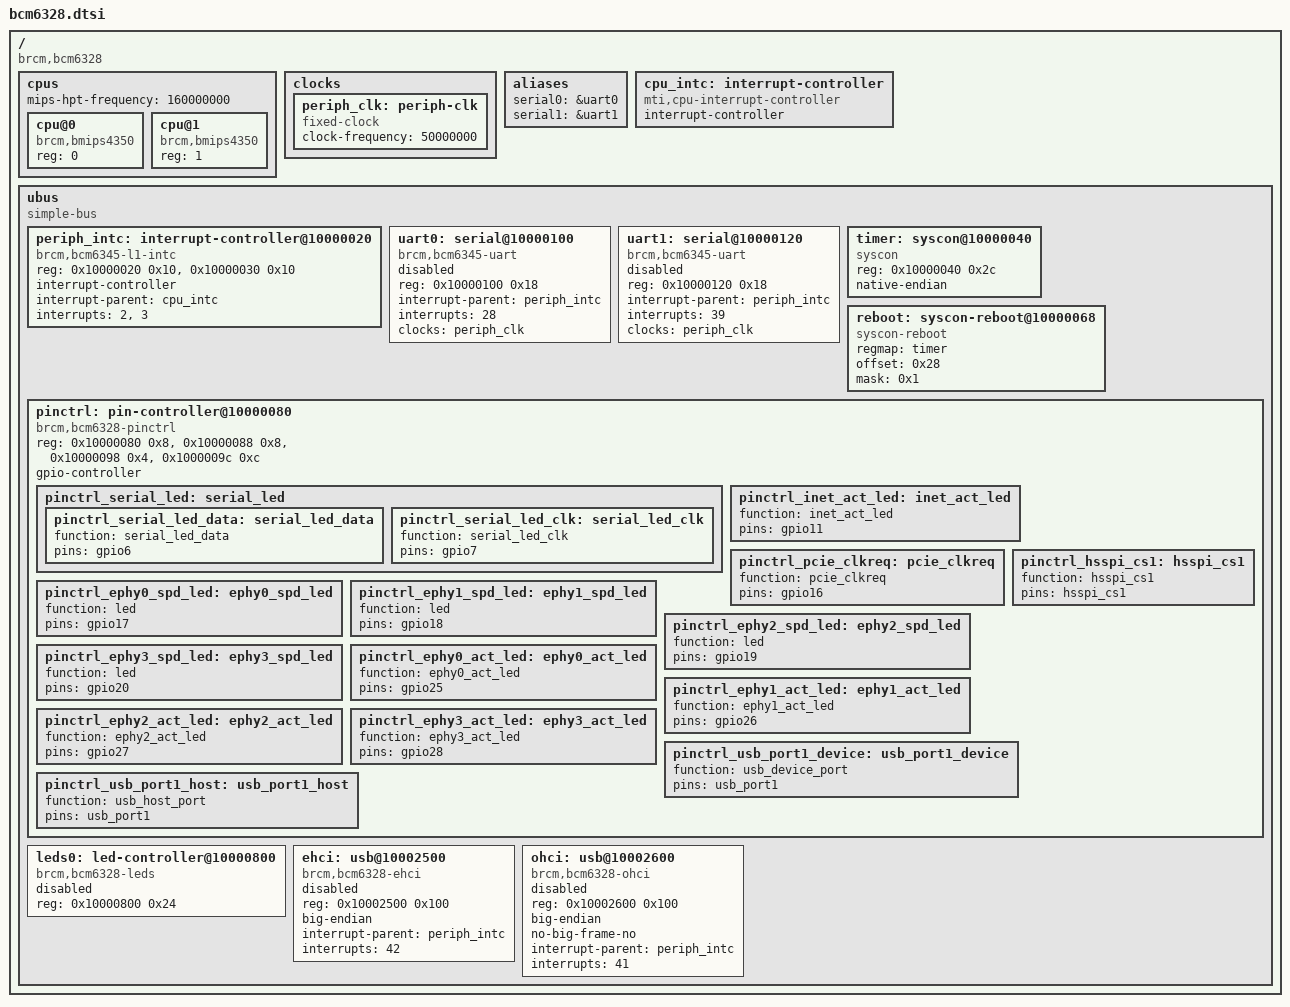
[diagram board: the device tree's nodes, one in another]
/ {
	#address-cells = <1>;
	#size-cells = <1>;
	compatible = "brcm,bcm6328";

	cpus {
		#address-cells = <1>;
		#size-cells = <0>;

		mips-hpt-frequency = <160000000>;

		cpu@0 {
			compatible = "brcm,bmips4350";
			device_type = "cpu";
			reg = <0>;
		};

		cpu@1 {
			compatible = "brcm,bmips4350";
			device_type = "cpu";
			reg = <1>;
		};
	};

	clocks {
		periph_clk: periph-clk {
			compatible = "fixed-clock";
			#clock-cells = <0>;
			clock-frequency = <50000000>;
		};
	};

	aliases {
		serial0 = &uart0;
		serial1 = &uart1;
	};

	cpu_intc: interrupt-controller {
		#address-cells = <0>;
		compatible = "mti,cpu-interrupt-controller";

		interrupt-controller;
		#interrupt-cells = <1>;
	};

	ubus {
		#address-cells = <1>;
		#size-cells = <1>;

		compatible = "simple-bus";
		ranges;

		periph_intc: interrupt-controller@10000020 {
			compatible = "brcm,bcm6345-l1-intc";
			reg = <0x10000020 0x10>,
			      <0x10000030 0x10>;

			interrupt-controller;
			#interrupt-cells = <1>;

			interrupt-parent = <&cpu_intc>;
			interrupts = <2>, <3>;
		};

		uart0: serial@10000100 {
			compatible = "brcm,bcm6345-uart";
			reg = <0x10000100 0x18>;
			interrupt-parent = <&periph_intc>;
			interrupts = <28>;
			clocks = <&periph_clk>;
			status = "disabled";
		};

		uart1: serial@10000120 {
			compatible = "brcm,bcm6345-uart";
			reg = <0x10000120 0x18>;
			interrupt-parent = <&periph_intc>;
			interrupts = <39>;
			clocks = <&periph_clk>;
			status = "disabled";
		};

		timer: syscon@10000040 {
			compatible = "syscon";
			reg = <0x10000040 0x2c>;
			native-endian;
		};

		reboot: syscon-reboot@10000068 {
			compatible = "syscon-reboot";
			regmap = <&timer>;
			offset = <0x28>;
			mask = <0x1>;
		};

		pinctrl: pin-controller@10000080 {
			compatible = "brcm,bcm6328-pinctrl";
			reg = <0x10000080 0x8>,
			      <0x10000088 0x8>,
			      <0x10000098 0x4>,
			      <0x1000009c 0xc>;
			reg-names = "dirout", "dat", "mode", "mux";

			gpio-controller;
			#gpio-cells = <2>;

			pinctrl_serial_led: serial_led {
				pinctrl_serial_led_data: serial_led_data {
					function = "serial_led_data";
					pins = "gpio6";
				};

				pinctrl_serial_led_clk: serial_led_clk {
					function = "serial_led_clk";
					pins = "gpio7";
				};
			};

			pinctrl_inet_act_led: inet_act_led {
				function = "inet_act_led";
				pins = "gpio11";
			};

			pinctrl_pcie_clkreq: pcie_clkreq {
				function = "pcie_clkreq";
				pins = "gpio16";
			};

			pinctrl_ephy0_spd_led: ephy0_spd_led {
				function = "led";
				pins = "gpio17";
			};

			pinctrl_ephy1_spd_led: ephy1_spd_led {
				function = "led";
				pins = "gpio18";
			};

			pinctrl_ephy2_spd_led: ephy2_spd_led {
				function = "led";
				pins = "gpio19";
			};

			pinctrl_ephy3_spd_led: ephy3_spd_led {
				function = "led";
				pins = "gpio20";
			};

			pinctrl_ephy0_act_led: ephy0_act_led {
				function = "ephy0_act_led";
				pins = "gpio25";
			};

			pinctrl_ephy1_act_led: ephy1_act_led {
				function = "ephy1_act_led";
				pins = "gpio26";
			};

			pinctrl_ephy2_act_led: ephy2_act_led {
				function = "ephy2_act_led";
				pins = "gpio27";
			};

			pinctrl_ephy3_act_led: ephy3_act_led {
				function = "ephy3_act_led";
				pins = "gpio28";
			};

			pinctrl_hsspi_cs1: hsspi_cs1 {
				function = "hsspi_cs1";
				pins = "hsspi_cs1";
			};

			pinctrl_usb_port1_device: usb_port1_device {
				function = "usb_device_port";
				pins = "usb_port1";
			};

			pinctrl_usb_port1_host: usb_port1_host {
				function = "usb_host_port";
				pins = "usb_port1";
			};
		};

		leds0: led-controller@10000800 {
			#address-cells = <1>;
			#size-cells = <0>;
			compatible = "brcm,bcm6328-leds";
			reg = <0x10000800 0x24>;
			status = "disabled";
		};

		ehci: usb@10002500 {
			compatible = "brcm,bcm6328-ehci", "generic-ehci";
			reg = <0x10002500 0x100>;
			big-endian;
			interrupt-parent = <&periph_intc>;
			interrupts = <42>;
			status = "disabled";
		};

		ohci: usb@10002600 {
			compatible = "brcm,bcm6328-ohci", "generic-ohci";
			reg = <0x10002600 0x100>;
			big-endian;
			no-big-frame-no;
			interrupt-parent = <&periph_intc>;
			interrupts = <41>;
			status = "disabled";
		};
	};
};
